# BL808 register map
File version: 0.1
Registers are access not given, no defined reset value unless marked. A register's access mark holds for its fields unless they carry their own. Offsets are from the block's base; [hi:lo] are bit positions; {n}, {i} and the like mark numbered series.

## SEC_ENG
Base 0x20004000
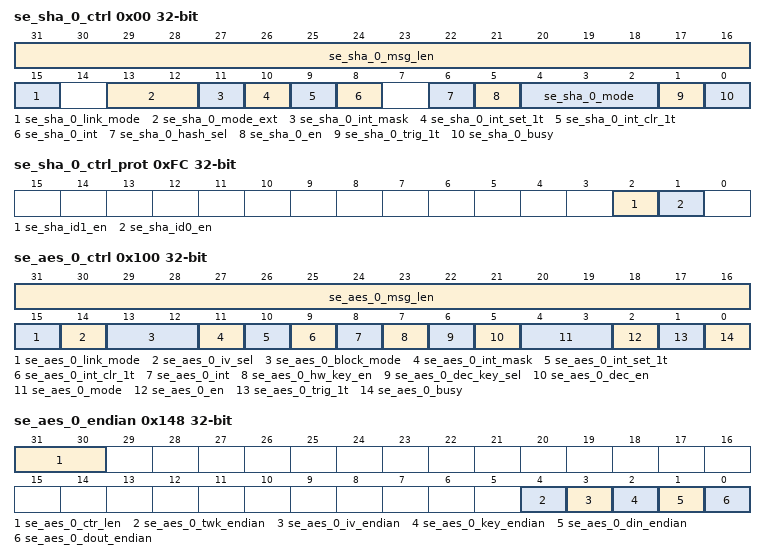
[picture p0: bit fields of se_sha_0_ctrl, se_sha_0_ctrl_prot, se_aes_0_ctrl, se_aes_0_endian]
0x00 se_sha_0_ctrl
  [31:16] se_sha_0_msg_len rw — number of 512-bit block
  [15] se_sha_0_link_mode rw — 1:enable sha link mode
  [13:12] se_sha_0_mode_ext rw — hash mode extention; 0:SHA 1:MD5 2:CRC-16 3:CRC-32
  [11] se_sha_0_int_mask rw
  [10] se_sha_0_int_set_1t write-once — 1:set interrupt
  [9] se_sha_0_int_clr_1t write-once — 1:clear interrupt
  [8] se_sha_0_int ro — interrupt value
  [6] se_sha_0_hash_sel rw — 0:new hash 1:accumulate last hash
  [5] se_sha_0_en rw — 1:enable sha engine
  [4:2] se_sha_0_mode rw — 0:SHA-256 1:SHA-224 2:SHA-1 3:SHA-1 4:SHA-512 5:SHA-384 6:SHA-512/224 7:SHA-512/256
  [1] se_sha_0_trig_1t write-once — 1:trigger sha engine
  [0] se_sha_0_busy ro — 1:sha engine busy
0x04 se_sha_0_msa rw
  [31:0] se_sha_0_msa — message source address
0x08 se_sha_0_status ro
  [31:0] se_sha_0_status
0x0C se_sha_0_endian
  [0] se_sha_0_dout_endian rw — 0:little-endian 1:big-endian
0x10 se_sha_0_hash_l_0 ro
  [31:0] se_sha_0_hash_l_0 — big-endian hash 0 (MSB)
{0x10+4i} se_sha_0_hash_l_{i} ro (i=1..6)
  [31:0] se_sha_0_hash_l_{i} — big-endian hash {i}
0x2C se_sha_0_hash_l_7 ro
  [31:0] se_sha_0_hash_l_7 — big-endian hash 7 (LSB)
0x30 se_sha_0_hash_h_0 ro
  [31:0] se_sha_0_hash_h_0 — big-endian hash 0 (MSB)
{0x30+4i} se_sha_0_hash_h_{i} ro (i=1..6)
  [31:0] se_sha_0_hash_h_{i} — big-endian hash {i}
0x4C se_sha_0_hash_h_7 ro
  [31:0] se_sha_0_hash_h_7 — big-endian hash 7 (LSB)
0x50 se_sha_0_link rw
  [31:0] se_sha_0_lca — aes link config address(word align)
0xFC se_sha_0_ctrl_prot
  [2] se_sha_id1_en rw — id1 access right
  [1] se_sha_id0_en rw — id0 access right
0x100 se_aes_0_ctrl access per field
  [31:16] se_aes_0_msg_len rw — number of 128-bit block
  [15] se_aes_0_link_mode rw — 1:enable aes link mode
  [14] se_aes_0_iv_sel rw — 0:new iv 1:same iv as last one
  [13:12] se_aes_0_block_mode rw — 0:ECB mode 1:CTR mode 2:CBC mode 3:XTS mode
  [11] se_aes_0_int_mask rw
  [10] se_aes_0_int_set_1t write-once — 1:set interrupt
  [9] se_aes_0_int_clr_1t write-once — 1:clear interrupt
  [8] se_aes_0_int ro — interrupt value
  [7] se_aes_0_hw_key_en rw — 0:sw key 1:hw key
  [6] se_aes_0_dec_key_sel rw — 0:new key 1:same key as last one
  [5] se_aes_0_dec_en rw — 0:encode 1:decode
  [4:3] se_aes_0_mode rw — 0:128-bit mode 1:256-bit mode 2:192-bit mode 3:128-bit double key mode
  [2] se_aes_0_en rw — 0:disable 1:enable aes
  [1] se_aes_0_trig_1t write-once — 1:trigger aes engine
  [0] se_aes_0_busy ro — 1:aes engine busy
0x104 se_aes_0_msa rw
  [31:0] se_aes_0_msa — message source address
0x108 se_aes_0_mda rw
  [31:0] se_aes_0_mda — message destination address
0x10C se_aes_0_status ro
  [31:0] se_aes_0_status
0x110 se_aes_0_iv_0 rw
  [31:0] se_aes_0_iv_0 — big endian initial vector (MSB)
0x114 se_aes_0_iv_1 rw
  [31:0] se_aes_0_iv_1 — big endian initial vector
0x118 se_aes_0_iv_2 rw
  [31:0] se_aes_0_iv_2 — big endian initial vector
0x11C se_aes_0_iv_3 rw
  [31:0] se_aes_0_iv_3 — big endian initial vector (LSB) (CTR mode: 32-bit counter initial value)
0x120 se_aes_0_key_0 rw
  [31:0] se_aes_0_key_0 — big endian aes key (aes-128/256 key MSB)
0x124 se_aes_0_key_1 rw
  [31:0] se_aes_0_key_1 — big endian aes key
0x128 se_aes_0_key_2 rw
  [31:0] se_aes_0_key_2 — big endian aes key
0x12C se_aes_0_key_3 rw
  [31:0] se_aes_0_key_3 — big endian aes key (aes-128 key LSB)
{0x120+4i} se_aes_0_key_{i} rw (i=4..6)
  [31:0] se_aes_0_key_{i} — big endian aes key
0x13C se_aes_0_key_7 rw
  [31:0] se_aes_0_key_7 — big endian aes key (aes-256 key LSB)
0x140 se_aes_0_key_sel
  [1:0] se_aes_0_key_sel rw
0x144 se_aes_1_key_sel
  [1:0] se_aes_1_key_sel rw
0x148 se_aes_0_endian
  [31:30] se_aes_0_ctr_len rw — 2'd0:4-byte counter, 2'd1:1-byte counter, 2'd2:2-byte counter, 2'd3:3-byte counter
  [4] se_aes_0_twk_endian rw — 0:little-endian 1:big-endian, default 1 for XTS
  [3] se_aes_0_iv_endian rw — 0:little-endian 1:big-endian
  [2] se_aes_0_key_endian rw — 0:little-endian 1:big-endian
  [1] se_aes_0_din_endian rw — 0:little-endian 1:big-endian
  [0] se_aes_0_dout_endian rw — 0:little-endian 1:big-endian
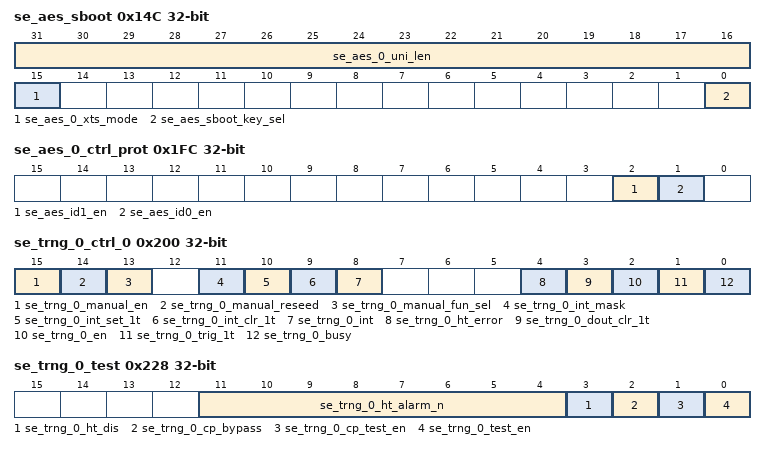
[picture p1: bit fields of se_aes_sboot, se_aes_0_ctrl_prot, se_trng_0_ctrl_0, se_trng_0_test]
0x14C se_aes_sboot
  [31:16] se_aes_0_uni_len rw — XTS data unit length: number of 128-bit blocks in a data unit, msg_len = N*uni_len
  [15] se_aes_0_xts_mode rw — 0: normal XTS, 1: XTS with only one data unit
  [0] se_aes_sboot_key_sel rw
0x150 se_aes_0_link rw
  [31:0] se_aes_0_lca — aes link config address(word align)
0x1FC se_aes_0_ctrl_prot
  [2] se_aes_id1_en rw — id1 access right
  [1] se_aes_id0_en rw — id0 access right
0x200 se_trng_0_ctrl_0
  [15] se_trng_0_manual_en rw — 1:enable manual mode
  [14] se_trng_0_manual_reseed rw — 1:clear reseed counter to zero and get new entropy
  [13] se_trng_0_manual_fun_sel rw — 0:go to instantiate state 1:go to generate state
  [11] se_trng_0_int_mask rw
  [10] se_trng_0_int_set_1t write-once — 1:set interrupt
  [9] se_trng_0_int_clr_1t write-once — 1:clear interrupt
  [8] se_trng_0_int ro — interrupt value
  [4] se_trng_0_ht_error ro — 1:health test error
  [3] se_trng_0_dout_clr_1t write-once — 1:clear trng dout to zero
  [2] se_trng_0_en rw — 0:disable 1:enable aes
  [1] se_trng_0_trig_1t write-once — 1:trigger trng engine
  [0] se_trng_0_busy ro — 1:trng engine busy
0x204 se_trng_0_status ro
  [31:0] se_trng_0_status
{0x208+4i} se_trng_0_dout_{i} ro (i=0..7)
  [31:0] se_trng_0_dout_{i} — random value
0x228 se_trng_0_test
  [11:4] se_trng_0_ht_alarm_n rw — health test alarm number 0:alarm if health test error >= 1 1:alarm if health test error >= 2
  [3] se_trng_0_ht_dis rw — 1:disable health test
  [2] se_trng_0_cp_bypass rw — 1:bypass conditional component
  [1] se_trng_0_cp_test_en rw — 1:enable trng conditional component test mode
  [0] se_trng_0_test_en rw — 1:enable trng test mode
0x22C se_trng_0_ctrl_1 rw
  [31:0] se_trng_0_reseed_n_lsb — reload seed when number of used random value is larger than reseed_n
0x230 se_trng_0_ctrl_2
  [15:0] se_trng_0_reseed_n_msb rw — reload seed when number of used random value is larger than reseed_n
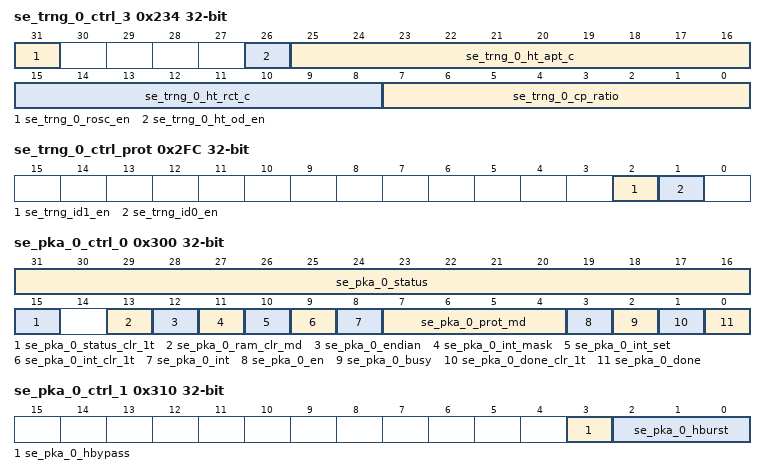
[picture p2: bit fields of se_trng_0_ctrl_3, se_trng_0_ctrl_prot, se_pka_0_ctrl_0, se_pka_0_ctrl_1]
0x234 se_trng_0_ctrl_3
  [31] se_trng_0_rosc_en rw — trng rosc enable
  [26] se_trng_0_ht_od_en rw — health test on demand test enable
  [25:16] se_trng_0_ht_apt_c rw — health test adaptive proportion test cut off value
  [15:8] se_trng_0_ht_rct_c rw — health test repetition count test cut off value
  [7:0] se_trng_0_cp_ratio rw — conditional component compression ration
{0x240+4i} se_trng_0_test_out_{i} ro (i=0..3)
  [31:0] se_trng_0_test_out_{i}
0x2FC se_trng_0_ctrl_prot
  [2] se_trng_id1_en rw — id1 access right
  [1] se_trng_id0_en rw — id0 access right
0x300 se_pka_0_ctrl_0
  [31:16] se_pka_0_status ro — [31]cmd_err, [30:26]cmd_err_idx[4:0] [25]opq_full, [24]last_opc, [23]err_cam_full, [22]err_div_by_0, [21]err_invalid_src0 [20]err_invalid_src1 [19]err_invalid_src2 [18]err_opq_overflow [17]err_unknown_opc [16]prime_fail
  [15] se_pka_0_status_clr_1t write-once
  [13] se_pka_0_ram_clr_md rw
  [12] se_pka_0_endian rw
  [11] se_pka_0_int_mask rw
  [10] se_pka_0_int_set rw — 1:set interrupt
  [9] se_pka_0_int_clr_1t write-once — 1:clear interrupt
  [8] se_pka_0_int ro — interrupt value
  [7:4] se_pka_0_prot_md rw
  [3] se_pka_0_en rw
  [2] se_pka_0_busy ro
  [1] se_pka_0_done_clr_1t write-once
  [0] se_pka_0_done ro
0x30C se_pka_0_seed rw
  [31:0] se_pka_0_seed
0x310 se_pka_0_ctrl_1
  [3] se_pka_0_hbypass rw
  [2:0] se_pka_0_hburst rw — 3'b000:single 3'b001:incr (undefined length) 3'b010:4-beat wrap 3'b011:4-beat incr 3'b100:8-beat wrap 3'b101:8-beat incr(default)
0x340 se_pka_0_rw rw
  [31:0] se_pka_0_rw — 0x340~0x35F single write for command
0x360 se_pka_0_rw_burst rw
  [31:0] se_pka_0_rw_burst — 0x360~0x37F burst write for data
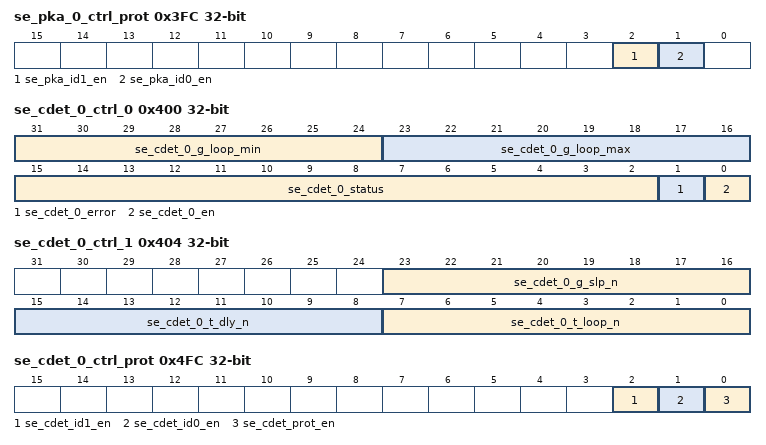
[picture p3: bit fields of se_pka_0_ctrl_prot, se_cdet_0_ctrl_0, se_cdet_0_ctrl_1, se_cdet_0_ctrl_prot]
0x3FC se_pka_0_ctrl_prot
  [2] se_pka_id1_en rw — id1 access right
  [1] se_pka_id0_en rw — id0 access right
0x400 se_cdet_0_ctrl_0 access per field
  [31:24] se_cdet_0_g_loop_min rw, [23:16] se_cdet_0_g_loop_max rw, [15:2] se_cdet_0_status ro, [1] se_cdet_0_error ro, [0] se_cdet_0_en rw
0x404 se_cdet_0_ctrl_1
  [23:16] se_cdet_0_g_slp_n rw, [15:8] se_cdet_0_t_dly_n rw, [7:0] se_cdet_0_t_loop_n rw
0x4FC se_cdet_0_ctrl_prot
  [2] se_cdet_id1_en rw — id1 access right
  [1] se_cdet_id0_en rw — id0 access right
  [0] se_cdet_prot_en rw — 1:control register protection enable
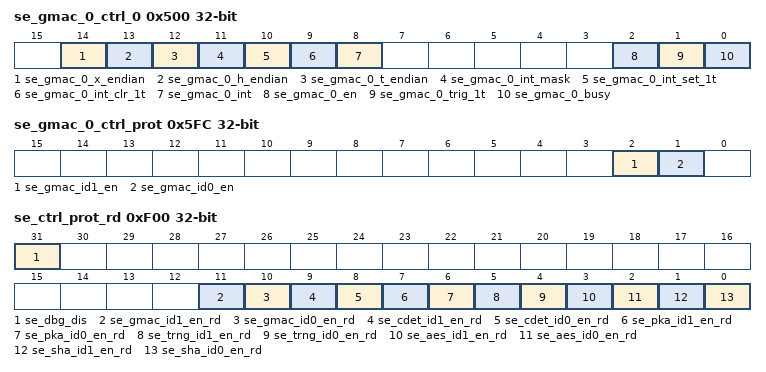
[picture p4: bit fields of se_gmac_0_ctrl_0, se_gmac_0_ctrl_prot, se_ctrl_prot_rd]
0x500 se_gmac_0_ctrl_0
  [14] se_gmac_0_x_endian rw — 0:little-endian 1:big-endian
  [13] se_gmac_0_h_endian rw — 0:little-endian 1:big-endian
  [12] se_gmac_0_t_endian rw — 0:little-endian 1:big-endian
  [11] se_gmac_0_int_mask rw — 1:mask interrupt
  [10] se_gmac_0_int_set_1t write-once — 1:set interrupt
  [9] se_gmac_0_int_clr_1t write-once — 1:clear interrupt
  [8] se_gmac_0_int ro — interrupt value
  [2] se_gmac_0_en rw — 0:disable 1:enable gmac
  [1] se_gmac_0_trig_1t write-once — 1:trigger gmac engine
  [0] se_gmac_0_busy ro — 1:gmac engine busy
0x504 se_gmac_0_lca rw
  [31:0] se_gmac_0_lca — gmac link config address(word align)
0x508 se_gmac_0_status ro
  [31:0] se_gmac_0_status
0x5FC se_gmac_0_ctrl_prot
  [2] se_gmac_id1_en rw — id1 access right
  [1] se_gmac_id0_en rw — id0 access right
0xF00 se_ctrl_prot_rd
  [31] se_dbg_dis ro — 1:disable aes debug mode
  [11] se_gmac_id1_en_rd ro — read only status of id1 access right
  [10] se_gmac_id0_en_rd ro — read only status of id0 access right
  [9] se_cdet_id1_en_rd ro — read only status of id1 access right
  [8] se_cdet_id0_en_rd ro — read only status of id0 access right
  [7] se_pka_id1_en_rd ro — read only status of id1 access right
  [6] se_pka_id0_en_rd ro — read only status of id0 access right
  [5] se_trng_id1_en_rd ro — read only status of id1 access right
  [4] se_trng_id0_en_rd ro — read only status of id0 access right
  [3] se_aes_id1_en_rd ro — read only status of id1 access right
  [2] se_aes_id0_en_rd ro — read only status of id0 access right
  [1] se_sha_id1_en_rd ro — read only status of id1 access right
  [0] se_sha_id0_en_rd ro — read only status of id0 access right
